AUTOSAR XML (schema 4-0-3)
package /App_FiM
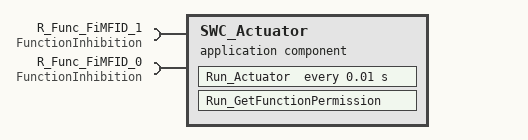
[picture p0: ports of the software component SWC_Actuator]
  application sw component type SWC_Actuator
    require port R_Func_FiMFID_1: client-com-spec=GetFunctionPermission, required-interface=FunctionInhibition
    require port R_Func_FiMFID_0: client-com-spec=GetFunctionPermission, required-interface=FunctionInhibition
    behavior SwcInternalBehavior_0
      timing event TE_Run_Actuator: start-on-event=Run_Actuator, period=0.01
      runnable Run_GetFunctionPermission
        sync call SSCP_GetFunctionPermission_FiMFID_0: operation=R_Func_FiMFID_0.GetFunctionPermission
        sync call SSCP_GetFunctionPermission_FiMFID_1: operation=R_Func_FiMFID_1.GetFunctionPermission
      runnable Run_Actuator: can-be-invoked-concurrently=true
